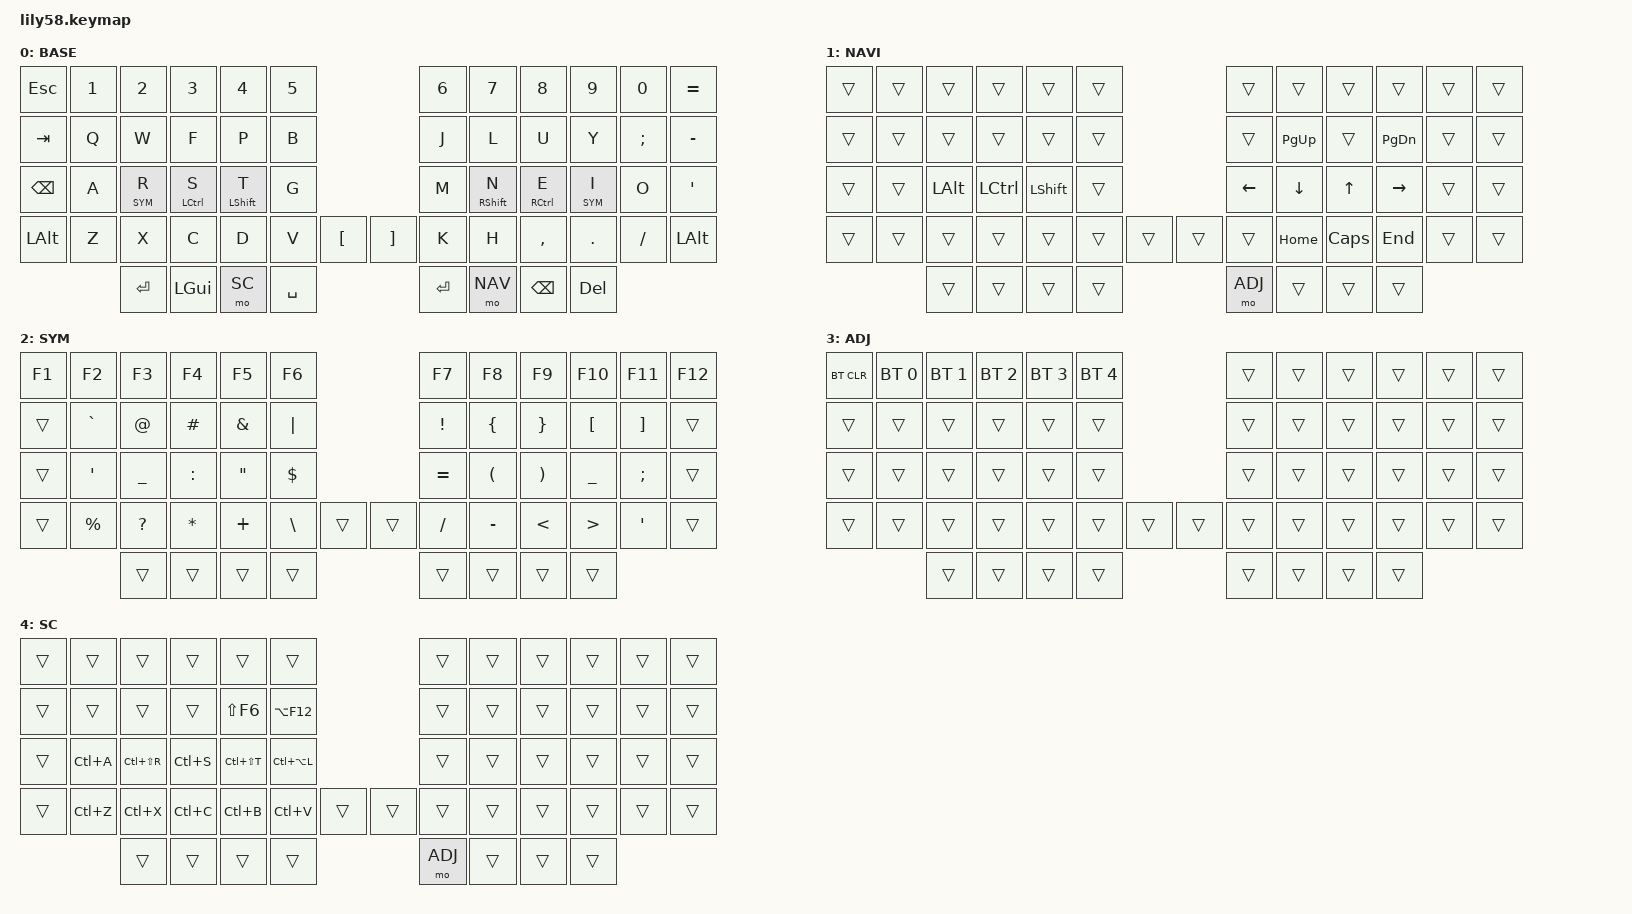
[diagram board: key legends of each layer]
/*
 * Copyright (c) 2020 The ZMK Contributors
 *
 * SPDX-License-Identifier: MIT
 */

#include <behaviors.dtsi>
#include <dt-bindings/zmk/keys.h>
#include <dt-bindings/zmk/bt.h>
#include <dt-bindings/zmk/ext_power.h>

#define BASE 0
#define NAV  1
#define SYM  2
#define ADJ  3
#define SC   4

&mt {
    quick-tap-ms = <100>;
    global-quick-tap;
    flavor = "tap-preferred";
    tapping-term-ms = <170>;
};

/ {
    combos {
        compatible = "zmk,combos";

            combo_left_gui {
                timeout-ms = <50>;
                key-positions = <13 14>;
                bindings = <&kp LGUI>;
            };
            combo_right_gui {
                timeout-ms = <50>;
                key-positions = <21 22>;
                bindings = <&kp LGUI>;
            };
            combo_left_alt {
                timeout-ms = <50>;
                key-positions = <38 39>;
                bindings = <&kp LALT>;
            };
            combo_right_alt {
                timeout-ms = <50>;
                key-positions = <46 47>;
                bindings = <&kp LALT>;
            };
    };

    macros {
    };

    keymap {
        compatible = "zmk,keymap";

        default_layer {
            // ┏━━━━━━━━━━━━━━━━━━━━━━━━━━━━━━━━━━━━━━━┓

            label = "BASE";
            display-name = "BASE";

            // ┗━━━━━━━━━━━━━━━━━━━━━━━━━━━━━━━━━━━━━━━┛
// ------------------------------------------------------------------------------------------------------------
// |  ESC  |  1  |  2  |  3    |  4   |  5   |                   |  6   |  7    |  8    |  9   |   0   |   +   |
// |  TAB  |  Q  |  W  |  F    |  P   |  B   |                   |  J   |  L    |  U    |  Y   |   ;   |   -   |
// |  BSPC |  A  | R $ |  S ⎈ |  T ⇧ |  G   |                   |  M   |  N ⇧  |  E ⎈  |  I $ |   O   |   '   |
// |  ALT  |  Z  |  X  |  C    |  D   |  V   |   "["  |  |  "]"  |  K   |  H    |  ,    |  .   |   /   |  ALT  |
//                     | ENTER | GUI  |  SC  |  SPACE |  | ENTER |  NAV |  BSPC |  DEL  |
            bindings = <
&kp ESC   &kp N1      &kp N2      &kp N3      &kp N4      &kp N5                     &kp N6      &kp N7      &kp N8      &kp N9      &kp N0   &kp EQUAL
&kp TAB   &kp Q       &kp W       &kp F       &kp P       &kp B                      &kp J       &kp L       &kp U       &kp Y       &kp SEMI &kp MINUS
&kp BSPC  &kp A       &lt SYM R   &mt LCTRL S &mt LSHFT T &kp G                      &kp M       &mt RSHFT N &mt RCTRL E &lt SYM I   &kp O    &kp SQT
&kp LALT  &kp Z       &kp X       &kp C       &kp D       &kp V  &kp LBKT   &kp RBKT &kp K       &kp H       &kp COMMA   &kp DOT     &kp FSLH &kp LALT
                      &kp RET     &kp LGUI    &mo SC      &kp SPACE                  &kp RET     &mo NAV     &kp BSPC    &kp DEL
            >;

            sensor-bindings = <&inc_dec_kp C_VOL_UP C_VOL_DN>;
        };

        nav_layer {
            // ┏━━━━━━━━━━━━━━━━━━━━━━━━━━━━━━━━━━━━━━━┓

            label = "NAVI";
            display-name = "NAVI";

            // ┗━━━━━━━━━━━━━━━━━━━━━━━━━━━━━━━━━━━━━━━┛
// ------------------------------------------------------------------------------------------------------------
// |     |     |     |      |      |      |                   |      |       |       |          |       |       |
// |     |     |     |      |      |      |                   |      | PAGEUP|       | PAGEDOWN |       |       |
// |     |     | ALT | CTRL | SHIFT|      |                   | LEFT | DOWN  |  UP   | RIGHT    |       |       |
// |     |     |     |      |      |      |        |  |       |      |  HOME |  CAPS |  END     |       |       |
//                   |      |      |      |        |  |  ADJ  |      |       |       |
            bindings = <
&trans     &trans       &trans      &trans      &trans      &trans                       &trans      &trans      &trans      &trans      &trans       &trans
&trans     &trans       &trans      &trans      &trans      &trans                       &trans      &kp PG_UP   &trans      &kp PG_DN   &trans       &trans
&trans     &trans       &kp LALT    &kp LCTRL   &kp LSHIFT  &trans                       &kp LEFT    &kp DOWN    &kp UP      &kp RIGHT   &trans       &trans
&trans     &trans       &trans      &trans      &trans      &trans    &trans   &trans    &trans      &kp HOME    &kp CAPS    &kp END     &trans       &trans
                                    &trans      &trans      &trans    &trans   &mo ADJ   &trans      &trans      &trans
            >;

            sensor-bindings = <&inc_dec_kp C_VOL_UP C_VOL_DN>;
        };

        sim_layer {
            // ┏━━━━━━━━━━━━━━━━━━━━━━━━━━━━━━━━━━━━━━━┓

            label = "SYM";
            display-name = "SYM";

            // ┗━━━━━━━━━━━━━━━━━━━━━━━━━━━━━━━━━━━━━━━┛
// ------------------------------------------------------------------------------------------------------------
// |  F1 |  F2 |  F3 |  F4  |  F5  |  F6  |                   |  F7  |  F8   |  F9   |  F10 |  F11  |  F12  |
// |     |  `  |  @  |   #  |  &   |  |   |                   |  !   |   {   |   }   |  [   |   ]   |       |
// |     |  '  |  _  |   :  |  "   |  $   |                   |  =   |   (   |   )   |  _   |   ;   |       |
// |     |  %  |  ?  |   *  |  +   |  \   |        |  |       |  /   |   -   |   <   |  >   |   '   |       |
//                   |      |      |      |        |  |       |      |       |       |
            bindings = <
&kp F1     &kp F2      &kp F3      &kp F4      &kp F5      &kp F6                          &kp F7      &kp F8     &kp F9       &kp F10     &kp F11      &kp F12
&trans     &kp GRAVE   &kp AT      &kp HASH    &kp AMPS    &kp PIPE                        &kp EXCL    &kp LBRC    &kp RBRC    &kp LBKT    &kp RBKT     &trans
&trans     &kp SQT     &kp UNDER   &kp COLON   &kp DQT     &kp DLLR                        &kp EQUAL   &kp LPAR    &kp RPAR    &kp UNDER   &kp SEMI     &trans
&trans     &kp PRCNT   &kp QMARK   &kp STAR    &kp PLUS    &kp BSLH  &trans         &trans &kp SLASH   &kp MINUS   &kp LT      &kp GT      &kp SQT      &trans
                                   &trans      &trans      &trans    &trans         &trans &trans      &trans      &trans
            >;

            sensor-bindings = <&inc_dec_kp C_VOL_UP C_VOL_DN>;
        };

        adjust_layer {
            // ┏━━━━━━━━━━━━━━━━━━━━━━━━━━━━━━━━━━━━━━━┓

            label = "ADJ";
            display-name = "ADJ";

            // ┗━━━━━━━━━━━━━━━━━━━━━━━━━━━━━━━━━━━━━━━┛
// ------------------------------------------------------------------------------------------------------------
// | BTCLR | BT1 | BT2 |  BT3 |  BT4 |  BT5 |                   |      |       |       |      |       |       |
// |       |     |     |      |      |      |                   |      |       |       |      |       |       |
// |       |     |     |      |      |      |                   |      |       |       |      |       |       |
// |       |     |     |      |      |      |        |  |       |      |       |       |      |       |       |
//                     |      |      |      |        |  |       |      |       |       |
            bindings = <
&bt BT_CLR &bt BT_SEL 0 &bt BT_SEL 1 &bt BT_SEL 2 &bt BT_SEL 3 &bt BT_SEL 4                &trans      &trans      &trans      &trans      &trans       &trans
&trans     &trans       &trans       &trans       &trans      &trans                       &trans      &trans      &trans      &trans      &trans       &trans
&trans     &trans       &trans       &trans       &trans      &trans                       &trans      &trans      &trans      &trans      &trans       &trans
&trans     &trans       &trans       &trans       &trans      &trans    &trans   &trans    &trans      &trans      &trans      &trans      &trans       &trans
                                     &trans       &trans      &trans    &trans   &trans    &trans      &trans      &trans
            >;

            sensor-bindings = <&inc_dec_kp C_VOL_UP C_VOL_DN>;
        };

        shortcut_layer {
            // ┏━━━━━━━━━━━━━━━━━━━━━━━━━━━━━━━━━━━━━━━┓

            label = "SC";
            display-name = "SC";

            // ┗━━━━━━━━━━━━━━━━━━━━━━━━━━━━━━━━━━━━━━━┛
// ----------------------------------------------------------------------------------------------------------------
// |     |            |            |            |            |            |                   |      |       |       |      |       |       |
// |     |            |            |            | SHIFT + F6 | ALT + F12  |                   |      |       |       |      |       |       |
// |     | CTRL + A   |CTRL+SHIFT+R|  CTRL + S  | CTRL+SHFT+T|CTRL+ALT+L |                   |      |       |       |      |       |       |
// |     | CTRL + Z   |  CTRL + X  |  CTRL + C  | CTRL + B   |  CTRL + V  |        |  |       |      |       |       |      |       |       |
//                                 |            |            |            |        |  |  ADJ  |      |       |       |
            bindings = <
&trans     &trans      &trans       &trans     &trans       &trans                         &trans      &trans      &trans      &trans      &trans       &trans
&trans     &trans      &trans       &trans     &kp LS(F6)   &kp LA(F12)                    &trans      &trans      &trans      &trans      &trans       &trans
&trans     &kp LC(A)   &kp LC(LS(R))&kp LC(S)  &kp LC(LS(T))&kp LC(LA(L))                  &trans      &trans      &trans      &trans      &trans       &trans
&trans     &kp LC(Z)   &kp LC(X)    &kp LC(C)  &kp LC(B)    &kp LC(V)   &trans   &trans    &trans      &trans      &trans      &trans      &trans       &trans
                                    &trans     &trans       &trans      &trans   &mo ADJ   &trans      &trans      &trans
            >;

            sensor-bindings = <&inc_dec_kp C_VOL_UP C_VOL_DN>;
        };
    };
};
